# A31R71x register map
Vendor: VENDOR ABOV Semiconductor Co., Ltd.; Series: A31R71x; File version: 1.0
CPU: CM0+ r0p1, little endian, no MPU, no FPU, VTOR, 2 interrupt priority bits
Registers are 32-bit, read-write, reset 0x0 unless marked. A register's access mark holds for its fields unless they carry their own. Offsets are from the block's base; [hi:lo] are bit positions; {n}, {i} and the like mark numbered series.

## LCD — LCD Driver
Base 0x40005000
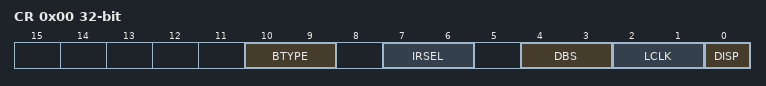
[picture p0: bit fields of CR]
0x00 CR — LCD Driver Control Register
  [10:9] BTYPE — LCD Bias Type Selection
    0=IntRBias (Internal Resistor Bias); 1=ExtRBias (External Resistor Bias); 2=CapBias (Capacitor Bias (Voltage Booster))
  [7:6] IRSEL — Internal LCD Bias Dividing Resistor Selection
    0=RLCD2 (60[kohm]); 1=RLCD1 (30[kohm]); 2=RLCD3 (120[kohm])
  [4:3] DBS — LCD Duty and Bias Selection
    0=4D3B (1/4 duty, 1/3 bias); 1=3D3B (1/3 duty, 1/3 bias); 2=3D2B (1/3 duty, 1/2 bias); 3=2D2B (1/2 duty, 1/2 bias)
  [2:1] LCLK — LCD Clock Selection (When fLCD = 32.768kHz)
    0=128Hz (32.768kHz(fLCD) / 256); 1=256Hz (32.768kHz(fLCD) / 128); 2=512Hz (32.768kHz(fLCD) / 64); 3=1024Hz (32.768kHz(fLCD) / 32)
  [0] DISP — LCD Display Control
    0=Off (Display off); 1=On (Normal display on)
0x04 CCR — LCD Contrast Control Register
  [3:0] VLCD — VLC2 Voltage Control when the capacitor bias is enabled
    0=Step0 (VLC2=1.00V when 1/2 Bias, VLC2=0.75V when 1/3 Bias); 1=Step1 (VLC2=1.05V when 1/2 Bias, VLC2=0.79V when 1/3 Bias); 2=Step2 (VLC2=1.10V when 1/2 Bias, VLC2=0.83V when 1/3 Bias); 3=Step3 (VLC2=1.15V when 1/2 Bias, VLC2=0.86V when 1/3 Bias); 4=Step4 (VLC2=1.20V when 1/2 Bias, VLC2=0.90V when 1/3 Bias); 5=Step5 (VLC2=1.25V when 1/2 Bias, VLC2=0.94V when 1/3 Bias); 6=Step6 (VLC2=1.30V when 1/2 Bias, VLC2=0.98V when 1/3 Bias); 7=Step7 (VLC2=1.35V when 1/2 Bias, VLC2=1.01V when 1/3 Bias); 8=Step8 (VLC2=1.40V when 1/2 Bias, VLC2=1.05V when 1/3 Bias); 9=Step9 (VLC2=1.45V when 1/2 Bias, VLC2=1.09V when 1/3 Bias); 10=Step10 (VLC2=1.50V when 1/2 Bias, VLC2=1.13V when 1/3 Bias); 11=Step11 (Not available when 1/2 Bias, VLC2=1.17V when 1/3 Bias); 12=Step12 (Not available when 1/2 Bias, VLC2=1.20V when 1/3 Bias); 13=Step13 (Not available when 1/2 Bias, VLC2=1.24V when 1/3 Bias); 14=Step14 (Not available when 1/2 Bias, VLC2=1.28V when 1/3 Bias); 15=Step15 (Not available when 1/2 Bias, VLC2=1.32V when 1/3 Bias)
{0x10+i} DR{i} 8-bit reset not defined (i=0..39) — LCD Display Data Register {i}

## CRC — Cyclic Redundancy Check and Checksum
Base 0x30001000
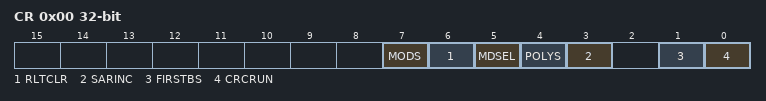
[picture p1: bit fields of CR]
0x00 CR — CRC/Checksum Control Register
  [7] MODS — User/Auto Mode Selection
    0=User Mode (Calculate every data written to the CRC_IN register); 1=Auto Mode (Calculate till CRC_SADR == CRC_EADR)
  [6] RLTCLR — CRC/Checksum Result Data Register (CRCRLT) Initialization
    0=NoEffect; 1=Initialize the CRC_RLT register with the value of CRC_INIT. (This bit is automatically cleared to '0' after operation.)
  [5] MDSEL — CRC/Checksum Selection
    0=CRC (Select CRC.); 1=Checksum (Select Checksum.)
  [4] POLYS — Polynomial Selection (CRC only)
    0=CRC16_CCITT (CRC16-CCITT (G1(x) = x16 + x12 + x5 + 1)); 1=CRC16 (CRC16 (G2(x) = x16 + x15 + x2 + 1))
  [3] SARINC — CRC/Checksum Start Address Auto Increment Control (User mode only)
    0=Disable (No effect.); 1=Enable (The CRC/Checksum start address register is incremented as the selected input size every writing to the CRC_IN register.)
  [1] FIRSTBS — First Shifted-in Selection (CRC only)
    0=msbFirst; 1=lsbFirst
  [0] CRCRUN — CRC/Checksum Start Control and Busy
    0=Stop (Not busy. The CRC operation can be finished by writing '0' to this bit while running.); 1=Start CRC operation. This bit is automatically cleared to '0' when the value of CRC_SADR register reaches the value of CRC_EADR register.
0x04 IN — CRC/Checksum Input Data Register
  [31:0] INDATA — CRC Input Data
0x08 RLT ro reset 0xFFFF — CRC/Checksum Result Data Register
  [15:0] RLTDATA — CRC Result Data
0x0C INIT — CRC/Checksum Initial Data Register
  [15:0] INIDATA — CRC Initial Data
0x10 SADR reset 0x10000000 — CRC/Checksum Start Address Register
  [31:2] SADR — CRC Start Address
0x14 EADR reset 0x1000FFFC — CRC/Checksum End Address Register
  [31:2] EADR — CRC End Address

## COA0 — Configuration Option Area Page 0: System Related Trimming Value
Base 0x1FFFF000
{0x0+4i} TRIM{i:02} ro reset 0xFFFFFFFF (reset mask 0x0) (i=0..31) — System Related Trim Value {i:02}

## COA1 — Configuration Option Area Page 1: User Option
Base 0x1FFFF200
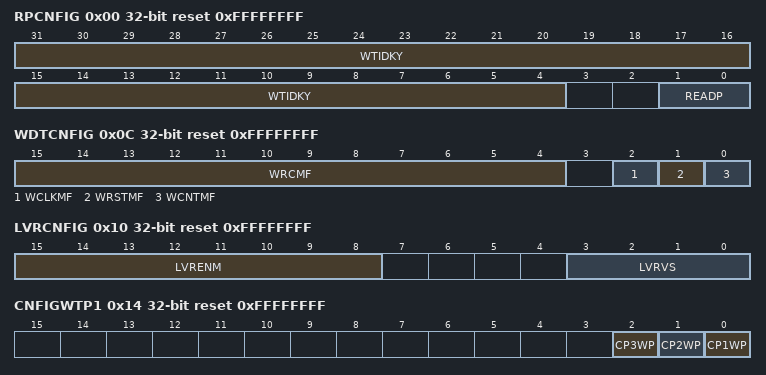
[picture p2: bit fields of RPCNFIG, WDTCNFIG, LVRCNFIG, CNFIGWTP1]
0x00 RPCNFIG ro reset 0xFFFFFFFF (reset mask 0xFFFFFFFC) — Configuration for Read Protection
  [31:4] WTIDKY — Write Identification Key (0x69c8a27)
    0x69C8A27=Value (Key Value (0x69c8a27))
  [1:0] READP — Read Protection for Flash Memory Area
    3=Level0 (No restriction for read/erase/write.); 2=Level1 (1. Not readable/erasable/writable by 'Debug' 2. Bulk erasable only by 'Debug' 3. Readable/erasable/writable by 'Instruction from Flash Memory and RAM'); 0=Level2 (1. Not readable/erasable/writable by 'Debug' / 'Instruction from RAM' 2. Bulk erasable only by 'Instruction from RAM' / 'Debug' 3. Readable/erasable/writable by 'Instruction from Flash Memory')
0x0C WDTCNFIG ro reset 0xFFFFFFFF (reset mask 0xFFFF0008) — Configuration for Watch-Dog Timer
  [15:4] WRCMF — Watch-Dog Timer RC Oscillator Master Configuration
    0x96D=By S/W (CLKSRCR Register) (0x96d); 0x2A7=AlwaysEnableExceptDeepSleep (Always Enable Except for Deep Sleep (0x2a7)); 0xFFF=AlwaysEnable
  [2] WCLKMF — Watch-Dog Timer Clock Selection Master Configuration
    0=By S/W (PPCLKSR Register); 1=AlwaysWDTRC
  [1] WRSTMF — Watch-Dog Timer Reset Enable Master Configuration
    0=AlwaysEnable; 1=By S/W (WDTCR Register)
  [0] WCNTMF — Watch-Dog Timer Counter Enable Master Configuration
    0=AlwaysEnable; 1=By S/W (WDTCR Register)
0x10 LVRCNFIG ro reset 0xFFFFFFFF (reset mask 0xFFFF00F0) — Configuration for Low Voltage Reset
  [15:8] LVRENM — LVR Reset Operation Control Master Configuration
    170=By S/W (LVRCR Register) (0xaa); 255=Always Enable (0xff)
  [3:0] LVRVS — LVR Voltage Selection
    15=1p62V (1.62V); 14=DNW14 (Do not write.); 13=DNW13 (Do not write.); 12=DNW12 (Do not write.); 11=2p00V (2.00V); 10=2p13V (2.13V); 9=2p28V (2.28V); 8=2p46V (2.46V); 7=2p67V (2.67V); 6=3p04V (3.04V); 5=3p20V (3.20V); 4=3p55V (3.55V); 3=3p75V (3.75V); 2=3p99V (3.99V); 1=4p25V (4.25V); 0=4p55 (4.55V)
0x14 CNFIGWTP1 ro reset 0xFFFFFFFF (reset mask 0xFFFFFFF8) — Erase/Write Protection for Configure Option Page 1/2/3
  [all] fields
    0=Enable protection. (Not erasable/writable by instruction); 1=Disable protection. (Erasable/writable by instruction)
  [2] CP3WP — Configure Option Page 3 Erase/Write Protection
  [1] CP2WP — Configure Option Page 2 Erase/Write Protection
  [0] CP1WP — Configure Option Page 1 Erase/Write Protection
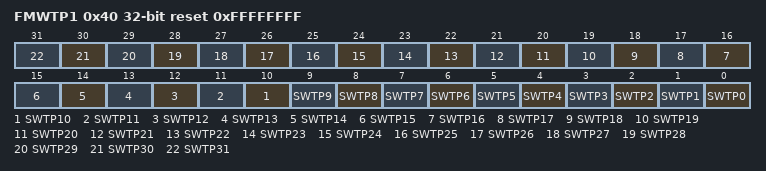
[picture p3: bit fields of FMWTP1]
0x40 FMWTP1 ro reset 0xFFFFFFFF (reset mask 0x0) — Erase/Write Protection for Flash Memory
  [all] fields
    0=Enable (Protect 'flash memory sector n erase/write'); 1=Disable (Permit 'flash memory sector n erase/write')
  [n] SWTP{n} (n=0..31) — Flash Memory Erase/Write Protection {n}

## COA2 — Configuration Option Area Page 2: User Data Area 0
Base 0x1FFFF400
Same registers: COA3 0x1FFFF600
{0x0+4i} UDATA{i:02} ro reset 0xFFFFFFFF (reset mask 0x0) (i=0..31) — User Data {i:02}
